AUTOSAR XML (schema 4-0-3)
standard types defined: Boolean, UInt32, UInt8
package /AUTOSAR_Platform/DataConstrs
  range DC_Boolean: raw 0..1
  range DC_UInt8: raw 0..255
package /PATAC/Facility/DataTypes/Implementation
  unit NoUnit: factor-si-to-unit=1, offset-si-to-unit=0
package /PATAC/MSM/ComponentTypes
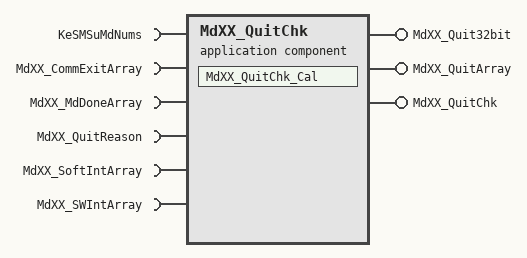
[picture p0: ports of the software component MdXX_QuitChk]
  application sw component type MdXX_QuitChk
    provide port MdXX_Quit32bit: nonqueued-sender-com-spec{data-element=MdXX_Quit32bit/Val, init-value=0}, provided-interface=MdXX_Quit32bit
    provide port MdXX_QuitArray: nonqueued-sender-com-spec{data-element=MdXX_QuitArray/Val, init-value=32 x 0}, provided-interface=MdXX_QuitArray
    provide port MdXX_QuitChk: server-com-spec{operation=Cal, queue-length=1}, provided-interface=MdXX_QuitChk
    6 x require port:
      KeSMSuMdNums: parameter-require-com-spec{init-value=26, parameter=Val}, required-interface=KeSMSuMdNums
      MdXX_CommExitArray: nonqueued-receiver-com-spec{data-element=MdXX_CommExitArray/Val, filter=data-filter-type=ALWAYS, init-value=32 x 0}, required-interface=MdXX_CommExitArray
      MdXX_MdDoneArray: nonqueued-receiver-com-spec{data-element=MdXX_MdDoneArray/Val, filter=data-filter-type=ALWAYS, init-value=32 x 0}, required-interface=MdXX_MdDoneArray
      MdXX_QuitReason: client-com-spec=Calc, required-interface=MdXX_QuitReason
      MdXX_SoftIntArray: nonqueued-receiver-com-spec{data-element=MdXX_SoftIntArray/Val, filter=data-filter-type=ALWAYS, init-value=32 x 0}, required-interface=MdXX_SoftIntArray
      MdXX_SWIntArray: nonqueued-receiver-com-spec{data-element=MdXX_SWIntArray/Val, filter=data-filter-type=ALWAYS, init-value=32 x 0}, required-interface=MdXX_SWIntArray
    behavior MdXX_QuitChk_InternalBehavior
      operation invoked event OIT_MdXX_QuitChk_Cal_MdXX_QuitChk_Cal: start-on-event=MdXX_QuitChk_Cal, operation=MdXX_QuitChk.Cal
      runnable MdXX_QuitChk_Cal
        data-receive-point-by-arguments:
          4 x access:
            SEND_MdXX_CommExitArray_Val: accessed-variable=MdXX_CommExitArray.Val
            SEND_MdXX_MdDoneArray_Val: accessed-variable=MdXX_MdDoneArray.Val
            SEND_MdXX_SoftIntArray_Val: accessed-variable=MdXX_SoftIntArray.Val
            SEND_MdXX_SWIntArray_Val: accessed-variable=MdXX_SWIntArray.Val
        data-send-points:
          access SEND_MdXX_Quit32bit_Val: accessed-variable=MdXX_Quit32bit.Val
          access SEND_MdXX_QuitArray_Val: accessed-variable=MdXX_QuitArray.Val
        parameter access PA_KeSMSuMdNums_Val: accessed-parameter=KeSMSuMdNums.Val
        sync call SC_MdXX_QuitReason_Calc: operation=MdXX_QuitReason.Calc, timeout=0
  swc implementation MdXX_QuitChk_Implementation: behavior=MdXX_QuitChk_InternalBehavior
    code-descriptors:
      code Default: artifact-descriptors=autosar-engineering-object={short-label=Default, category=SWSRC}
package /PATAC/MSM/ModeAdjust/CalPortInterface
  parameter interface KeSMSuMdNums
    parameter data prototype Val: sw-calibration-access=READ-WRITE, type=UInt8
package /PATAC/MSM/ModeAdjust/CompuMethods
  compu method MdRspLocal2: 0=MdRsp_None, 1=MdRsp_RecallSuccessfully, 2=MdRsp_RecallUnsuccessfully_LocalInterrupt, 3=MdRsp_RecallUnsuccessfully_NonEnghSpace, 4=MdRsp_RecallOngoing, 5=MdRsp_TargetPositionAlready, 6=MdRsp_LowPower, 7=MdRsp_CrashStat, 8=MdRsp_ThdRwOccupt, 9=MdRsp_PosNotLrn, 10=MdRsp_NotParkStat, 11=MdRsp_SpdNotCorrt
package /PATAC/MSM/ModeAdjust/DataType
  4 x impl type, all with sw-calibration-access=READ-ONLY, type-emitter=RTE:
    array1x32_Boolean: category=ARRAY
      element Element: array-size=32, array-size-semantics=FIXED-SIZE, implementation-data-type=Implementation/Boolean
    Array1x32_Uint8: category=ARRAY
      element Element: array-size=32, array-size-semantics=FIXED-SIZE, implementation-data-type=UInt8
    MdRspLocal2: category=VALUE, base-type=UInt8, compu-method=MdRspLocal2
    MdXX_QuitArray: category=ARRAY
      element Element: array-size=32, array-size-semantics=FIXED-SIZE, compu-method=MdRspLocal2, implementation-data-type=MdRspLocal2
package /PATAC/MSM/ModeAdjust/PortInterface
  client server interface MdXX_QuitChk
    operation Cal
  client server interface MdXX_QuitReason
    operation Calc
      5 x arg, all with server-argument-impl-policy=USE-ARGUMENT-TYPE:
        MdDone: type=UInt8, direction=IN
        ExitCond: type=DataTypes/Boolean, direction=IN
        SWInt: type=DataTypes/Boolean, direction=IN
        SoftInt: type=DataTypes/Boolean, direction=IN
        MdQuitReason: type=MdRspLocal2, direction=OUT
  6 x sender receiver interface:
    MdXX_CommExitArray: invalidation-policy{data-element=MdXX_CommExitArray/Val, handle-invalid=DONT-INVALIDATE}
      data Val: type=array1x32_Boolean
    MdXX_MdDoneArray: invalidation-policy{data-element=MdXX_MdDoneArray/Val, handle-invalid=DONT-INVALIDATE}
      data Val: type=Array1x32_Uint8
    MdXX_Quit32bit: invalidation-policy{data-element=MdXX_Quit32bit/Val, handle-invalid=DONT-INVALIDATE}
      data Val: type=UInt32
    MdXX_QuitArray: invalidation-policy{data-element=MdXX_QuitArray/Val, handle-invalid=DONT-INVALIDATE}
      data Val: type=MdXX_QuitArray
    MdXX_SoftIntArray: invalidation-policy{data-element=MdXX_SoftIntArray/Val, handle-invalid=DONT-INVALIDATE}
      data Val: type=array1x32_Boolean
    MdXX_SWIntArray: invalidation-policy{data-element=MdXX_SWIntArray/Val, handle-invalid=DONT-INVALIDATE}
      data Val: type=array1x32_Boolean
